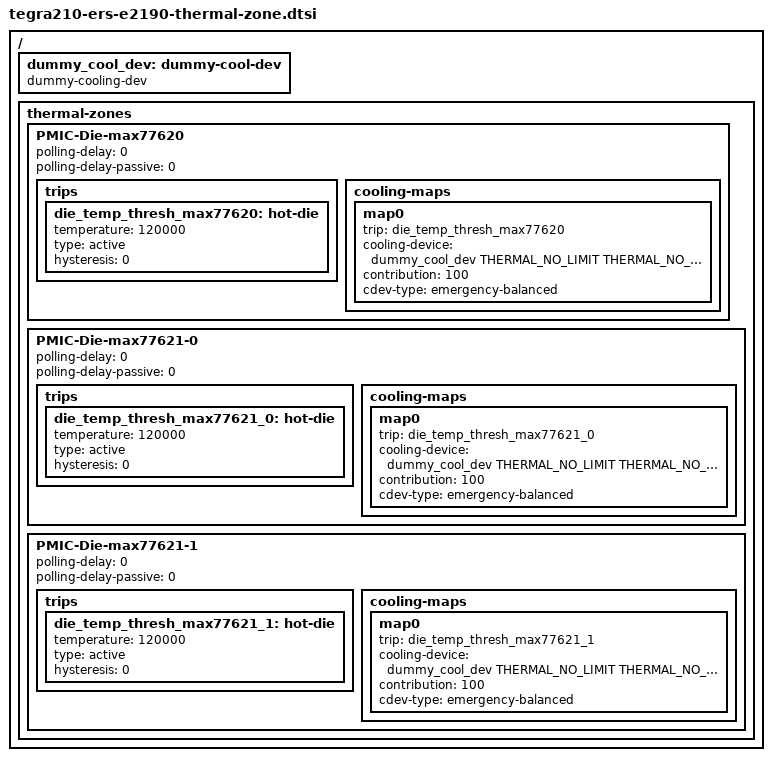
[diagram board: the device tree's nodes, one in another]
#include <dt-bindings/thermal/thermal.h>

/ {

	dummy_cool_dev: dummy-cool-dev {
		compatible = "dummy-cooling-dev";
		#cooling-cells = <2>; /* min followed by max */
	};

	thermal-zones {
		PMIC-Die-max77620 {
			polling-delay = <0>; /* milliseconds */
			polling-delay-passive = <0>; /* milliseconds */

			trips {
				die_temp_thresh_max77620: hot-die {
					temperature = <120000>;
					type = "active";
					hysteresis = <0>;
				};
			};

			cooling-maps {
				map0 {
					trip = <&die_temp_thresh_max77620>;
					cooling-device = <&dummy_cool_dev THERMAL_NO_LIMIT
								THERMAL_NO_LIMIT>;
					contribution = <100>;
					cdev-type = "emergency-balanced";
				};
			};
		};

		PMIC-Die-max77621-0 {
			polling-delay = <0>; /* milliseconds */
			polling-delay-passive = <0>; /* milliseconds */

			trips {
				die_temp_thresh_max77621_0: hot-die {
					temperature = <120000>;
					type = "active";
					hysteresis = <0>;
				};
			};

			cooling-maps {
				map0 {
					trip = <&die_temp_thresh_max77621_0>;
					cooling-device = <&dummy_cool_dev THERMAL_NO_LIMIT
								THERMAL_NO_LIMIT>;
					contribution = <100>;
					cdev-type = "emergency-balanced";
				};
			};
		};

		PMIC-Die-max77621-1 {
			polling-delay = <0>; /* milliseconds */
			polling-delay-passive = <0>; /* milliseconds */

			trips {
				die_temp_thresh_max77621_1: hot-die {
					temperature = <120000>;
					type = "active";
					hysteresis = <0>;
				};
			};

			cooling-maps {
				map0 {
					trip = <&die_temp_thresh_max77621_1>;
					cooling-device = <&dummy_cool_dev THERMAL_NO_LIMIT
								THERMAL_NO_LIMIT>;
					contribution = <100>;
					cdev-type = "emergency-balanced";
				};
			};
		};
	};
};
